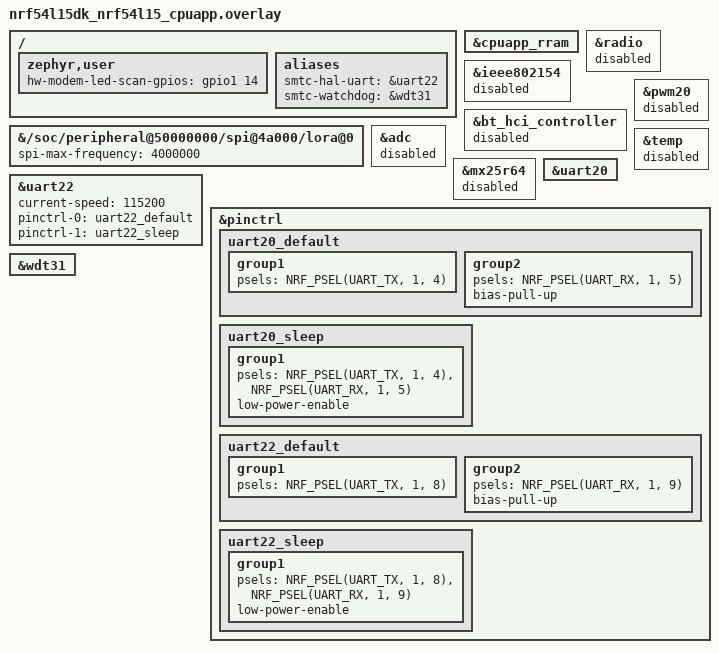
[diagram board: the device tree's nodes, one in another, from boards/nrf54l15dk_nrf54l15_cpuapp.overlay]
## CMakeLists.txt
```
# Copyright (c) 2024 Semtech Corporation
# SPDX-License-Identifier: Apache-2.0

cmake_minimum_required(VERSION 3.13.1)

find_package(Zephyr REQUIRED HINTS $ENV{ZEPHYR_BASE})
project(hw_modem)

# Use serialization files from USP module
set(USP_HW_MODEM_DIR ${ZEPHYR_USP_MODULE_DIR}/examples/main_examples/hw_modem)

zephyr_include_directories(
    ${ZEPHYR_USP_ZEPHYR_CMAKE_DIR}/include/zephyr/usp
    ${USP_HW_MODEM_DIR}
)

# Nanopb and RAC serialization
target_include_directories(app PRIVATE
  ${USP_HW_MODEM_DIR}/serialization/nanopb
  ${USP_HW_MODEM_DIR}/serialization/generated
  ${USP_HW_MODEM_DIR}/serialization/helpers
)

target_sources(app PRIVATE
  ${CMAKE_CURRENT_SOURCE_DIR}/src/main.c
  ${CMAKE_CURRENT_SOURCE_DIR}/src/hw_modem.c
  ${CMAKE_CURRENT_SOURCE_DIR}/src/unified_uart.c
  ${USP_HW_MODEM_DIR}/cmd_parser.c
  ${USP_HW_MODEM_DIR}/git_version.c

  # Nanopb core (copied to generated/ by build.sh)
  ${USP_HW_MODEM_DIR}/serialization/generated/pb_common.c
  ${USP_HW_MODEM_DIR}/serialization/generated/pb_decode.c
  ${USP_HW_MODEM_DIR}/serialization/generated/pb_encode.c

  # Generated protobuf
  ${USP_HW_MODEM_DIR}/serialization/generated/smtc_rac_context.pb.c

  # Helpers
  ${USP_HW_MODEM_DIR}/serialization/helpers/rac_context_converter.c
)

if(CONFIG_LORA_BASICS_MODEM_GEOLOCATION)
    target_sources(app PRIVATE
        ${CMAKE_CURRENT_SOURCE_DIR}/../../lbm/geolocation/src/geolocation_bsp.c
    )
endif()

# Apply the same compile definitions as LBM library
# Link against the INTERFACE library that contains all LBM compile definitions
target_link_libraries(app PRIVATE lbm_compile_definitions)

# Apply the same compile definitions as FLRP library
# Link against the INTERFACE library that contains all FLRP compile definitions
if(CONFIG_USP_FLRP)
    target_link_libraries(app PRIVATE flrp_compile_definitions)
endif()
```

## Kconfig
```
# Copyright (c) 2024 Semtech Corporation
# SPDX-License-Identifier: Apache-2.0

config USE_FLRP
	bool "Hardware modem FLRC burst commands (0xB0-0xB2)"
	default n
	depends on SEMTECH_LR20XX
	help
	  When enabled, adds FLRC burst commands and a ~20 KB static buffer in
	  cmd_parser. Use the FLRC protocol (FLRP). Requires a LR20XX radio.
	  Disable on RAM-constrained targets.

# src/unified_uart.c multiplexes modem data and log traces on a single UART using a binary
# framed protocol, and registers a custom log backend (log_backend_unified_uart) that routes
# log output through unified_uart_tx(). Zephyr's stock UART log backend and console write
# raw, unframed bytes straight to the same UART and would corrupt that framing, and printk()
# must stay routed through the log subsystem (not the UART driver) to reach the custom
# backend too. The backend's own char-out batching (src/unified_uart.c) also assumes
# immediate (synchronous, per-call) log processing. These are hard requirements of this
# sample, not tunable build options, so they are forced here instead of being left as
# settings in prj.conf.

config LOG_BACKEND_UART
	default n

config UART_CONSOLE
	default n

config LOG_OUTPUT
	default y

config LOG_PRINTK
	default y

# LOG_MODE_IMMEDIATE is a member of Zephyr's anonymous LOG_MODE choice (subsys/logging/
# Kconfig.mode): Kconfig does not let "default" or "select" force a choice member from
# another file (both are no-ops on choice symbols), so it stays set directly in prj.conf
# as CONFIG_LOG_MODE_IMMEDIATE=y — the mechanism Kconfig actually supports for picking a
# choice option from application configuration.

source "Kconfig.zephyr"
```

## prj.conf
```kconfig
# Copyright (c) 2024 Semtech Corporation
# SPDX-License-Identifier: Apache-2.0

CONFIG_DEBUG=y
CONFIG_NO_OPTIMIZATIONS=y
CONFIG_DEBUG_OPTIMIZATIONS=y
CONFIG_DEBUG_THREAD_INFO=y
CONFIG_DCACHE=n

CONFIG_USE_SEGGER_RTT=n

# ------------------------------ General configuration -------------------------

# stack size (Zephyr boilerplate + 2048 required by Semtech)
CONFIG_MAIN_STACK_SIZE=6144
CONFIG_STACK_SENTINEL=y

# some opereations will be triggered from the system workq, so match above stack size
CONFIG_SYSTEM_WORKQUEUE_STACK_SIZE=4096

# heap size
CONFIG_HEAP_MEM_POOL_SIZE=0

CONFIG_LOG=y
# CONFIG_LOG_BACKEND_UART, CONFIG_LOG_OUTPUT, CONFIG_LOG_PRINTK and CONFIG_UART_CONSOLE are
# forced in Kconfig (not user-tunable here): see the comment above the unified_uart section
# in ./Kconfig.
# CONFIG_LOG_MODE_IMMEDIATE is a choice member and Kconfig can't force those from another
# file, so it stays set here — see the comment in ./Kconfig for why it is still required.
CONFIG_LOG_MODE_IMMEDIATE=y

CONFIG_LOG_BACKEND_SHOW_COLOR=n

CONFIG_TEST_RANDOM_GENERATOR=y

CONFIG_SERIAL=y
CONFIG_UART_INTERRUPT_DRIVEN=y

CONFIG_FLASH=y

# ------------------------------ Transceiver driver ----------------------------

CONFIG_LORA_BASICS_MODEM_DRIVERS=y
# We chose to disable intermediate thread between IRQ and USP RAC Thread to make timestamping is as fast as possible
CONFIG_LORA_BASICS_MODEM_DRIVERS_EVENT_TRIGGER_NO_THREAD=y
#CONFIG_LORA_BASICS_MODEM_DRIVERS_EVENT_TRIGGER_GLOBAL_THREAD=n
#CONFIG_LORA_BASICS_MODEM_DRIVERS_EVENT_TRIGGER_OWN_THREAD=n

CONFIG_REBOOT=y

# ------------------------------ LoRa Basics Modem -----------------------------

#CONFIG_LORA_BASICS_MODEM=n
CONFIG_USP_LORA_BASICS_MODEM=y


CONFIG_LORA_BASICS_MODEM_RP2_103=y
CONFIG_LORA_BASICS_MODEM_ENABLE_ALL_REGIONS=y

# LBM LoRaWAN uses software crypto (default). FLRP adds separate *_fast sources via
# modules/flrc_protocol/common.cmake.

CONFIG_LORA_BASICS_MODEM_CLASS_B=y
CONFIG_LORA_BASICS_MODEM_CLASS_C=y
CONFIG_LORA_BASICS_MODEM_MULTICAST=y
CONFIG_LORA_BASICS_MODEM_CSMA=y

CONFIG_LORA_BASICS_MODEM_ALC_SYNC=y
CONFIG_LORA_BASICS_MODEM_ALC_SYNC_V2=y

CONFIG_LORA_BASICS_MODEM_FUOTA=y
CONFIG_LORA_BASICS_MODEM_FUOTA_V2=y
CONFIG_LORA_BASICS_MODEM_FUOTA_FMP=y
CONFIG_LORA_BASICS_MODEM_FUOTA_MPA=y

CONFIG_LORA_BASICS_MODEM_ALMANAC=y
CONFIG_LORA_BASICS_MODEM_STREAM=y
CONFIG_LORA_BASICS_MODEM_LFU=y
CONFIG_LORA_BASICS_MODEM_DEVICE_MANAGEMENT=y
CONFIG_LORA_BASICS_MODEM_GEOLOCATION=n
CONFIG_LORA_BASICS_MODEM_STORE_AND_FORWARD=y
# CONFIG_LORA_BASICS_MODEM_BEACON_TX=y
CONFIG_LORA_BASICS_MODEM_RELAY_RX=y
CONFIG_LORA_BASICS_MODEM_RELAY_TX=y

# ------------------------------ USP -----------------------------
CONFIG_USP=y
CONFIG_USP_FLRP=n # NOTE: enabling this feature will add a static 20Kb buffer
CONFIG_USP_MAIN_THREAD=n

# The following parameter disable nRF54L15 FLASH RRAM buffer size to prevent from issue being investigating
CONFIG_NRF_RRAM_WRITE_BUFFER_SIZE=0

# ------------------------------ Debug -----------------------------
```

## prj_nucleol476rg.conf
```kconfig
# Copyright (c) 2024 Semtech Corporation
# SPDX-License-Identifier: Apache-2.0

CONFIG_DEBUG=y
CONFIG_NO_OPTIMIZATIONS=y
CONFIG_DEBUG_OPTIMIZATIONS=y
CONFIG_DEBUG_THREAD_INFO=y
CONFIG_DCACHE=n

CONFIG_USE_SEGGER_RTT=n

# ------------------------------ General configuration -------------------------

# stack size (Zephyr boilerplate + 2048 required by Semtech)
CONFIG_MAIN_STACK_SIZE=12288
CONFIG_STACK_SENTINEL=y




# some opereations will be triggered from the system workq, so match above stack size
CONFIG_SYSTEM_WORKQUEUE_STACK_SIZE=8192

# heap size
CONFIG_HEAP_MEM_POOL_SIZE=8192

CONFIG_LOG=y
CONFIG_LOG_BACKEND_UART=y
CONFIG_LOG_BUFFER_SIZE=4096

CONFIG_LOG_BACKEND_SHOW_COLOR=n

CONFIG_TEST_RANDOM_GENERATOR=y

CONFIG_SERIAL=y
CONFIG_UART_INTERRUPT_DRIVEN=y

CONFIG_FLASH=y

# ------------------------------ Transceiver driver ----------------------------

CONFIG_LORA_BASICS_MODEM_DRIVERS=y
CONFIG_LORA_BASICS_MODEM_DRIVERS_EVENT_TRIGGER_GLOBAL_THREAD=y

CONFIG_REBOOT=y

# ------------------------------ LoRa Basics Modem -----------------------------

#CONFIG_LORA_BASICS_MODEM=n
CONFIG_USP_LORA_BASICS_MODEM=y


CONFIG_LORA_BASICS_MODEM_RP2_103=y
CONFIG_LORA_BASICS_MODEM_ENABLE_ALL_REGIONS=y

CONFIG_LORA_BASICS_MODEM_CRYPTOGRAPHY_SOFT=n

CONFIG_LORA_BASICS_MODEM_CLASS_B=y
CONFIG_LORA_BASICS_MODEM_CLASS_C=y
CONFIG_LORA_BASICS_MODEM_MULTICAST=y
CONFIG_LORA_BASICS_MODEM_CSMA=y

CONFIG_LORA_BASICS_MODEM_ALC_SYNC=y
CONFIG_LORA_BASICS_MODEM_ALC_SYNC_V2=y

CONFIG_LORA_BASICS_MODEM_FUOTA=y
CONFIG_LORA_BASICS_MODEM_FUOTA_V2=y
CONFIG_LORA_BASICS_MODEM_FUOTA_FMP=y
CONFIG_LORA_BASICS_MODEM_FUOTA_MPA=y

CONFIG_LORA_BASICS_MODEM_ALMANAC=y
CONFIG_LORA_BASICS_MODEM_STREAM=y
CONFIG_LORA_BASICS_MODEM_LFU=y
CONFIG_LORA_BASICS_MODEM_DEVICE_MANAGEMENT=y
CONFIG_LORA_BASICS_MODEM_GEOLOCATION=y
CONFIG_LORA_BASICS_MODEM_STORE_AND_FORWARD=y
# CONFIG_LORA_BASICS_MODEM_BEACON_TX=y
CONFIG_LORA_BASICS_MODEM_RELAY_RX=y
CONFIG_LORA_BASICS_MODEM_RELAY_TX=y

# ------------------------------ USP -----------------------------
CONFIG_USP=y
CONFIG_USP_MAIN_THREAD=n
CONFIG_PICOLIBC_USE_MODULE=n
CONFIG_NEWLIB_LIBC=y

# ------------------------------ NUCLEO L476RG CLOCK DRIFT -----------------------------
CONFIG_CORTEX_M_SYSTICK=n
CONFIG_STM32_LPTIM_TIMER=y
CONFIG_CLOCK_CONTROL=y
CONFIG_PM=y
```

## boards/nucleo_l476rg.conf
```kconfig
# Copyright (c) 2024 Semtech Corporation
# SPDX-License-Identifier: Apache-2.0

# ------------------------------ NUCLEO L476RG CLOCK DRIFT -----------------------------

# PM is required for STM32_LPTIM_TIMER but we DON'T want device PM
# Only enable system PM, not device PM to avoid UART suspension
CONFIG_PM_DEVICE=n
CONFIG_PM=y

# Prevent deep sleep to keep UART operational
# Use custom PM policy to control sleep depth
CONFIG_PM_POLICY_CUSTOM=y

# Disable SYSTICK and use LPTIM on LSE for precise clock without drift
CONFIG_CORTEX_M_SYSTICK=n
CONFIG_STM32_LPTIM_TIMER=y
CONFIG_CLOCK_CONTROL=y
CONFIG_RESET=y

# Note: LPTIM clock source (LSE 32768Hz) is configured in the device tree overlay

# Uncomment those lines to activate DMA on STM32L476RG
CONFIG_DMA=y
CONFIG_DMA_STM32=y
CONFIG_SPI_STM32_DMA=y
CONFIG_SPI_STM32_INTERRUPT=n
CONFIG_SPI_ASYNC=n
```

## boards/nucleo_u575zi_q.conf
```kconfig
# PM is required for STM32_LPTIM_TIMER but we DON'T want device PM
# Only enable system PM, not device PM to avoid UART suspension
CONFIG_PM_DEVICE=n
CONFIG_PM=y

# Prevent deep sleep to keep UART operational
# Use custom PM policy to control sleep depth
CONFIG_PM_POLICY_CUSTOM=y

# Disable SYSTICK and use LPTIM on LSE for precise clock without drift
CONFIG_CORTEX_M_SYSTICK=n
CONFIG_STM32_LPTIM_TIMER=y
CONFIG_CLOCK_CONTROL=y
```

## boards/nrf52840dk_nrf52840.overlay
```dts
/*
 * Copyright (c) 2024 Semtech Corporation
 *
 * SPDX-License-Identifier: Apache-2.0
 */

/ {
	zephyr,user {
		/* PINS used for the HW modem sample. */
		hw-modem-led-scan-gpios = <&gpio0 5 GPIO_ACTIVE_HIGH>;
	};

	aliases {
		/* Specify which UART is used for communication as input for the hw modem tester */
		smtc-hal-uart = &uart1;
		smtc-watchdog = &wdt;
	};
};

//Label for flash controller (needed cause we need properties, and we grab alias in user code)
smtc_flash: &flash0 {};

&spi1 {
	status = "disabled";
};

&qspi {
	status = "disabled"; //Needed because we use pin P0.24
};

//Delete HFC for uart0 as we use RTS pin
&uart0 {
	/delete-property/ hw-flow-control;
};

&uart1 {
	status = "okay";

	current-speed = <115200>;

	pinctrl-0 = <&uart1_default_alt>;
	pinctrl-1 = <&uart1_sleep_alt>;
	pinctrl-names = "default", "sleep";
	/delete-property/ hw-flow-control;
};

&pinctrl {
	//Disable Flow Control for uart0 (user log uart)
	uart0_default: uart0_default {
		group1 {
			psels = <NRF_PSEL(UART_TX, 0, 6)>;
		};
		group2 {
			psels = <NRF_PSEL(UART_RX, 0, 8)>;
			bias-pull-up;
		};
	};

	uart0_sleep: uart0_sleep {
		group1 {
			psels = <NRF_PSEL(UART_TX, 0, 6)>,
					<NRF_PSEL(UART_RX, 0, 8)>;
			low-power-enable;
		};
	};

	uart1_default_alt: uart1_default_alt {
		group1 {
			psels = <NRF_PSEL(UART_TX, 0, 11)>,
					<NRF_PSEL(UART_RX, 0, 12)>;
		};
	};

	uart1_sleep_alt: uart1_sleep_alt {
		group1 {
			psels = <NRF_PSEL(UART_TX, 0, 11)>,
					<NRF_PSEL(UART_RX, 0, 12)>;
			low-power-enable;
		};
	};
};

&wdt {
	status = "okay";
};

&arduino_i2c {
        /delete-property/ zephyr,concat-buf-size;
};
```

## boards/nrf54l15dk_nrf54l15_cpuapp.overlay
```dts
/*
 * Copyright (c) 2024 Semtech Corporation
 *
 * SPDX-License-Identifier: Apache-2.0
 */

/ {
	zephyr,user {
		/* PINS used for the HW modem sample. */
		hw-modem-led-scan-gpios = <&gpio1 14 GPIO_ACTIVE_HIGH>; //LED3
	};

	aliases {
		/* Specify which UART is used for communication as input for the hw modem tester */
		smtc-hal-uart = &uart22;
		smtc-watchdog = &wdt31;
	};
};

//Label for flash controller (needed cause we need properties, and we grab alias in user code)
smtc_flash: &cpuapp_rram {};

// Set SPI freq @4MHz
&{/soc/peripheral@50000000/spi@4a000/lora@0} {
	spi-max-frequency = < 4000000 >;
};

&radio {
	status = "disabled";
};

&ieee802154 {
	status = "disabled";
};

&bt_hci_controller {
	status = "disabled";
};

&pwm20 {
	status = "disabled";
};

&adc {
	status = "disabled";
};

&temp {
	status = "disabled";
};

&mx25r64 {
	status = "disabled";
};

//Bridge uart (no need flow control)
&uart22 {
	status = "okay";
	current-speed = <115200>;
	pinctrl-0 = <&uart22_default>;
	pinctrl-1 = <&uart22_sleep>;
	pinctrl-names = "default", "sleep";
	/delete-property/ hw-flow-control;
};

//User uart (for logging)
&uart20 {
	status = "okay";
	// disable-rx; //Disabling RX allows a gain of ~200µA, totally disabling uart allows another gain of ~200µA
	/delete-property/ hw-flow-control;
};

&pinctrl {
	uart20_default: uart20_default {
		group1 {
			psels = <NRF_PSEL(UART_TX, 1, 4)>
			// ,<NRF_PSEL(UART_RTS, 0, 2)>
			;
		};
		group2 {
			psels = <NRF_PSEL(UART_RX, 1, 5)>
			// ,<NRF_PSEL(UART_CTS, 0, 3)>
			;
			bias-pull-up;
		};
	};

	uart20_sleep: uart20_sleep {
		group1 {
			psels = <NRF_PSEL(UART_TX, 1, 4)>,
					<NRF_PSEL(UART_RX, 1, 5)>
					// ,<NRF_PSEL(UART_RTS, 0, 2)>
					// ,<NRF_PSEL(UART_CTS, 0, 3)>
					;
			low-power-enable;
		};
	};

	uart22_default: uart22_default {
		group1 {
			psels = <NRF_PSEL(UART_TX, 1, 8)> //BUTTON2
			// ,<NRF_PSEL(UART_RTS, 0, 2)>
			;
		};
		group2 {
			psels = <NRF_PSEL(UART_RX, 1, 9)> //BUTTON1
			// ,<NRF_PSEL(UART_CTS, 0, 3)>
			;
			bias-pull-up;
		};
	};

	uart22_sleep: uart22_sleep {
		group1 {
			psels = <NRF_PSEL(UART_TX, 1, 8)>,
					<NRF_PSEL(UART_RX, 1, 9)>
					// ,<NRF_PSEL(UART_RTS, 0, 2)>
					// ,<NRF_PSEL(UART_CTS, 0, 3)>
					;
			low-power-enable;
		};
	};
};

&wdt31 {
	status = "okay";
};
```

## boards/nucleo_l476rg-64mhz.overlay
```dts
/*
 * Copyright (c) 2024 Semtech Corporation
 *
 * SPDX-License-Identifier: Apache-2.0
 */

/ {
	zephyr,user {
		/* PINS used for the HW modem sample. */
		hw-modem-led-scan-gpios = <&gpiob 5 GPIO_ACTIVE_HIGH>;
	};

	aliases {
		/* Host UART auto-selected from chosen zephyr,console (usart2 = ST-Link VCP). */
		smtc-watchdog = &iwdg;
	};
};

//Label for flash controller (needed cause we need properties, and we grab alias in user code)
smtc_flash: &flash0 {};

// Uncomment the following 3 sections to set board @64MHz (instead of 80) and SPI@16MHz (instead of 10)
&pll {
	mul-n = <16>; 
};

&rcc {
	clock-frequency = < 64000000 >;
};

&{/soc/spi@40013000/lora@0} {
	spi-max-frequency = < 16000000 >; 
};
// END 64MHz --------------------------------------------------------

&lptim1 {
	// 0x80000000 = 31th bit of register RCC_APB1ENR1 (LPTIM1_EN)
	// We could also use ST macro : STM32_CLOCK(APB1, 31) to produce same result.
	// LPTIM1_SEL(3) = Set the LPTIM1SEL bits of RCC_CCIPR to 0b11 (source = LSE)
	clocks = <&rcc STM32_CLOCK_BUS_APB1 0x80000000>, 
		 <&rcc STM32_SRC_LSE LPTIM1_SEL(3)>;
	status = "okay";
};

&spi3 {
	status = "disabled";
};

&iwdg {
	status = "disabled";
};

&arduino_spi {
	/delete-property/ overrun-character;
};

&arduino_i2c {
        /delete-property/ zephyr,concat-buf-size;
};
```

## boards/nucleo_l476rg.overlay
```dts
/*
 * Copyright (c) 2024 Semtech Corporation
 *
 * SPDX-License-Identifier: Apache-2.0
 */

/ {
	/*
	 * Host UART is auto-selected by the sample from chosen "zephyr,console"
	 * (usart2 = ST-Link VCP on this board, set by the base board DTS).
	 * No "smtc-hal-uart" alias needed here; define one only to force a
	 * different UART than the console.
	 */
	zephyr,user {
		/* PINS used for the HW modem sample. */
		hw-modem-led-scan-gpios = <&gpiob 5 GPIO_ACTIVE_HIGH>;
	};

	aliases {
		smtc-watchdog = &iwdg;
	};
};

//Label for flash controller (needed cause we need properties, and we grab alias in user code)
smtc_flash: &flash0 {};

&lptim1 {
	clocks = <&rcc STM32_CLOCK_BUS_APB1 0x80000000>,
		 <&rcc STM32_SRC_LSE LPTIM1_SEL(3)>;
	status = "okay";
};

&spi3 {
	status = "disabled";
};

&iwdg {
	status = "disabled";
};

&arduino_spi {
	/delete-property/ overrun-character;
};

&arduino_i2c {
        /delete-property/ zephyr,concat-buf-size;
};

// Set SPI freq @10MHz for this sample
&{/soc/spi@40013000/lora@0} {
	spi-max-frequency = < 10000000 >; 
};

&arduino_spi {
        /delete-property/ overrun-character;
        // Uncomment those 3 lines to activate DMA on STM32L4
        dmas = <&dma1 3 1 (STM32_DMA_PERIPH_TX | STM32_DMA_PRIORITY_HIGH)>,
               <&dma1 2 1 (STM32_DMA_PERIPH_RX | STM32_DMA_PRIORITY_HIGH)>;
        dma-names = "tx", "rx";
};

// Uncomment those 3 lines to activate DMA on STM32L4
&dma1 {
        status = "okay";
};
```

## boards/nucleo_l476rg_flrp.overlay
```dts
/*
 * Copyright (c) 2024 Semtech Corporation
 *
 * SPDX-License-Identifier: Apache-2.0
 */

/ {
	zephyr,user {
		/* PINS used for the HW modem sample. */
		hw-modem-led-scan-gpios = <&gpiob 5 GPIO_ACTIVE_HIGH>;
	};

	aliases {
		/* Host UART auto-selected from chosen zephyr,console (usart2 = ST-Link VCP). */
		smtc-watchdog = &iwdg;
	};
};

//Label for flash controller (needed cause we need properties, and we grab alias in user code)
smtc_flash: &flash0 {};

&lptim1 {
	clocks = <&rcc STM32_CLOCK_BUS_APB1 0x80000000>,
		 <&rcc STM32_SRC_LSE LPTIM1_SEL(3)>;
	status = "okay";
};

&spi3 {
	status = "disabled";
};

&iwdg {
	status = "disabled";
};

&arduino_spi {
	/delete-property/ overrun-character;
};

&arduino_i2c {
        /delete-property/ zephyr,concat-buf-size;
};

// Set SPI freq @10MHz for this sample
&{/soc/spi@40013000/lora@0} {
	spi-max-frequency = < 10000000 >; 
        pa-ramp-time = <17>; // 272us
};

&arduino_spi {
        /delete-property/ overrun-character;
        // Uncomment those 3 lines to activate DMA on STM32L4
        dmas = <&dma1 3 1 (STM32_DMA_PERIPH_TX | STM32_DMA_PRIORITY_HIGH)>,
               <&dma1 2 1 (STM32_DMA_PERIPH_RX | STM32_DMA_PRIORITY_HIGH)>;
        dma-names = "tx", "rx";
};

// Uncomment those 3 lines to activate DMA on STM32L4
&dma1 {
        status = "okay";
};
```

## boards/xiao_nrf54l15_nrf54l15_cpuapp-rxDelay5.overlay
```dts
/*
 * Copyright (c) 2024 Semtech Corporation
 *
 * SPDX-License-Identifier: Apache-2.0
 */

/ {
	zephyr,user {
		/* PINS used for the HW modem sample. */
	};

	aliases {
		/* Host UART auto-selected from chosen zephyr,console (uart20 = USB serial). */
		smtc-watchdog = &wdt31;
	};
};

// Set rx-delay to 5*64MHz clock cycles
&xiao_spi {
	rx-delay = <5>;
};

// Host link on the USB serial (uart20 = console), already enabled @115200 by the
// base board DTS. Just turn off the unused header UART.
&uart21 {
	status = "disabled";
};

&adc {
	status = "disabled";
};

&i2c22 {
	status = "disabled";
};

&i2c30 {
	status = "disabled";
};

&wdt31 {
	status = "okay";
};

// Override xiao_nrf54l15 default configuration for USP applications
// Disable boot-on for RF switch regulators to save power

&rfsw_ctl {
	/delete-property/ regulator-boot-on;
};

&rfsw_pwr {
	/delete-property/ regulator-boot-on;
};

&vbat_pwr {
	/delete-property/ regulator-boot-on;
};
```

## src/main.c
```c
/**
 * @file      main.c
 *
 * @brief     Application main
 *
 * The Clear BSD License
 * Copyright Semtech Corporation 2025. All rights reserved.
 *
 * Redistribution and use in source and binary forms, with or without
 * modification, are permitted (subject to the limitations in the disclaimer
 * below) provided that the following conditions are met:
 *     * Redistributions of source code must retain the above copyright
 *       notice, this list of conditions and the following disclaimer.
 *     * Redistributions in binary form must reproduce the above copyright
 *       notice, this list of conditions and the following disclaimer in the
 *       documentation and/or other materials provided with the distribution.
 *     * Neither the name of the Semtech corporation nor the
 *       names of its contributors may be used to endorse or promote products
 *       derived from this software without specific prior written permission.
 *
 * NO EXPRESS OR IMPLIED LICENSES TO ANY PARTY'S PATENT RIGHTS ARE GRANTED BY
 * THIS LICENSE. THIS SOFTWARE IS PROVIDED BY THE COPYRIGHT HOLDERS AND
 * CONTRIBUTORS "AS IS" AND ANY EXPRESS OR IMPLIED WARRANTIES, INCLUDING, BUT
 * NOT LIMITED TO, THE IMPLIED WARRANTIES OF MERCHANTABILITY AND FITNESS FOR A
 * PARTICULAR PURPOSE ARE DISCLAIMED. IN NO EVENT SHALL SEMTECH CORPORATION BE
 * LIABLE FOR ANY DIRECT, INDIRECT, INCIDENTAL, SPECIAL, EXEMPLARY, OR
 * CONSEQUENTIAL DAMAGES (INCLUDING, BUT NOT LIMITED TO, PROCUREMENT OF
 * SUBSTITUTE GOODS OR SERVICES; LOSS OF USE, DATA, OR PROFITS; OR BUSINESS
 * INTERRUPTION) HOWEVER CAUSED AND ON ANY THEORY OF LIABILITY, WHETHER IN
 * CONTRACT, STRICT LIABILITY, OR TORT (INCLUDING NEGLIGENCE OR OTHERWISE)
 * ARISING IN ANY WAY OUT OF THE USE OF THIS SOFTWARE, EVEN IF ADVISED OF THE
 * POSSIBILITY OF SUCH DAMAGE.
 */

#include <stdbool.h>
#include <stdint.h>
#include <zephyr/kernel.h>
#include <zephyr/irq.h>
#include <zephyr/logging/log.h>

#include <zephyr/lorawan_lbm/lorawan_hal_init.h>
#include <smtc_modem_utilities.h>
#include <smtc_core_hal.h>
#include <smtc_rac_api.h>
#if defined( CONFIG_USP_FLRP )
#include <smtc_flrp_api.h>
#endif

#include "hw_modem.h"
#include "cmd_parser.h"
#include "git_version.h"

LOG_MODULE_REGISTER( hw_modem, LOG_LEVEL_INF );

/**
 * @brief Watchdog counter reload value during sleep (The period must be lower than MCU watchdog
 * period (here 32s))
 */
#define WATCHDOG_RELOAD_PERIOD_MS 20000

/* lr11xx radio context and its use in the ralf layer */
static const struct device* transceiver = DEVICE_DT_GET( DT_ALIAS( lora_transceiver ) );

/**
 * @brief Callback for modem hal
 */
static uint8_t prv_get_battery_level_cb( void )
{
    return 98;
}

/**
 * @brief Callback for modem hal
 */
static uint16_t prv_get_battery_voltage_cb( void )
{
    return 3300;
}

/**
 * @brief Callback for modem hal
 */
static int8_t prv_get_temperature_cb( void )
{
    return 25;
}

#ifdef CONFIG_LORA_BASICS_MODEM_FUOTA
static uint32_t prv_get_hw_version_for_fuota( void )
{
    return 1;
}

static uint32_t prv_get_fw_version_for_fuota( void )
{
    return 1;
}

static uint8_t prv_get_fw_status_available_for_fuota( void )
{
    return 1;
}

static uint32_t prv_get_next_fw_version_for_fuota( void )
{
    return 1;
}

static uint8_t prv_get_fw_delete_status_for_fuota( uint32_t version )
{
    return 0;
}

/* Callbacks for HAL implementation */
static struct lorawan_fuota_cb prv_fuota_cb = {
    .get_hw_version          = prv_get_hw_version_for_fuota,
    .get_fw_version          = prv_get_fw_version_for_fuota,
    .get_fw_status_available = prv_get_fw_status_available_for_fuota,
    .get_next_fw_version     = prv_get_next_fw_version_for_fuota,
    .get_fw_delete_status    = prv_get_fw_delete_status_for_fuota,
};

#endif /* CONFIG_LORA_BASICS_MODEM_FUOTA */

void main_hw_modem( void );

int main( void )
{
    unsigned int irq_lock_key;
    uint32_t     sleep_time_ms = 0;
    bool         is_sleep_ok;

    lorawan_smtc_modem_hal_init( transceiver );
    lorawan_register_battery_level_callback( prv_get_battery_level_cb );
    lorawan_register_battery_voltage_callback( prv_get_battery_voltage_cb );
    lorawan_register_temperature_callback( prv_get_temperature_cb );
#ifdef CONFIG_LORA_BASICS_MODEM_FUOTA
    lorawan_register_fuota_callbacks( &prv_fuota_cb );
#endif

    cmd_parser_set_transceiver_context( ( void* ) transceiver );

    /* NOTE: watchdogs aren't fully implemented in those samples. */
    /* hal_watchdog_init(); */

    // Initialize RAC
    smtc_rac_init( );

    if( hw_modem_init( ) )
    {
        LOG_ERR( "Could not initialize hardware modem, exiting." );
        return 0;
    }

    LOG_INF( "Modem is starting" );
    LOG_DBG( "Commit SHA1: %s", get_software_git_commit( ) );
    LOG_DBG( "Commit date: %s", get_software_git_date( ) );
    LOG_DBG( "Build date: %s", get_software_build_date( ) );

    while( 1 )
    {
        /* Check if a command is available */
        if( hw_modem_is_a_cmd_available( ) == true )
        {
            /* Command may generate work for the stack, so drop down to
             * smtc_modem_run_engine().
             */
            hw_modem_process_cmd( );
        }

        /* Modem process launch */
        sleep_time_ms = smtc_modem_run_engine( );
        smtc_rac_run_engine( );
#if defined( CONFIG_USP_FLRP )
        smtc_flrp_run_engine( );
        if( smtc_rac_is_irq_flag_pending( ) )
        {
            continue;
        }
#endif

        /* Check sleep conditions (no command available and low power is possible) */
        irq_lock_key = irq_lock( );
        is_sleep_ok  = ( hw_modem_is_a_cmd_available( ) == false ) && ( hw_modem_is_low_power_ok( ) == true ) &&
                      ( smtc_modem_is_irq_flag_pending( ) == false );
        irq_unlock( irq_lock_key );

        if( is_sleep_ok )
        {
            uint32_t real_sleep_time_ms = MIN( sleep_time_ms, WATCHDOG_RELOAD_PERIOD_MS );

            LOG_DBG( "Sleeping for %d ms", real_sleep_time_ms );
            smtc_modem_hal_interruptible_msleep( real_sleep_time_ms );
        }
    }
    return 0;
}
```

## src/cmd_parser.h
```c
/**
 * @file      cmd_parser.h
 *
 * @brief     cmd_parser implementation
 *
 * The Clear BSD License
 * Copyright Semtech Corporation 2025. All rights reserved.
 *
 * Redistribution and use in source and binary forms, with or without
 * modification, are permitted (subject to the limitations in the disclaimer
 * below) provided that the following conditions are met:
 *     * Redistributions of source code must retain the above copyright
 *       notice, this list of conditions and the following disclaimer.
 *     * Redistributions in binary form must reproduce the above copyright
 *       notice, this list of conditions and the following disclaimer in the
 *       documentation and/or other materials provided with the distribution.
 *     * Neither the name of the Semtech corporation nor the
 *       names of its contributors may be used to endorse or promote products
 *       derived from this software without specific prior written permission.
 *
 * NO EXPRESS OR IMPLIED LICENSES TO ANY PARTY'S PATENT RIGHTS ARE GRANTED BY
 * THIS LICENSE. THIS SOFTWARE IS PROVIDED BY THE COPYRIGHT HOLDERS AND
 * CONTRIBUTORS "AS IS" AND ANY EXPRESS OR IMPLIED WARRANTIES, INCLUDING, BUT
 * NOT LIMITED TO, THE IMPLIED WARRANTIES OF MERCHANTABILITY AND FITNESS FOR A
 * PARTICULAR PURPOSE ARE DISCLAIMED. IN NO EVENT SHALL SEMTECH CORPORATION BE
 * LIABLE FOR ANY DIRECT, INDIRECT, INCIDENTAL, SPECIAL, EXEMPLARY, OR
 * CONSEQUENTIAL DAMAGES (INCLUDING, BUT NOT LIMITED TO, PROCUREMENT OF
 * SUBSTITUTE GOODS OR SERVICES; LOSS OF USE, DATA, OR PROFITS; OR BUSINESS
 * INTERRUPTION) HOWEVER CAUSED AND ON ANY THEORY OF LIABILITY, WHETHER IN
 * CONTRACT, STRICT LIABILITY, OR TORT (INCLUDING NEGLIGENCE OR OTHERWISE)
 * ARISING IN ANY WAY OUT OF THE USE OF THIS SOFTWARE, EVEN IF ADVISED OF THE
 * POSSIBILITY OF SUCH DAMAGE.
 */

#ifndef CMD_PARSER_H__
#define CMD_PARSER_H__

#include <stdint.h>

#include "smtc_modem_api.h"

#ifdef __cplusplus
extern "C" {
#endif

/**
 * @brief Host command opcode definition
 */
typedef enum host_cmd_id_e
{
    CMD_RESET                                = 0x00,
    CMD_SET_REGION                           = 0x01,
    CMD_GET_REGION                           = 0x02,
    CMD_JOIN_NETWORK                         = 0x03,
    CMD_REQUEST_UPLINK                       = 0x04,
    CMD_GET_EVENT                            = 0x05,
    CMD_GET_DOWNLINK_DATA                    = 0x06,
    CMD_GET_DOWNLINK_METADATA                = 0x07,
    CMD_GET_JOIN_EUI                         = 0x08,
    CMD_SET_JOIN_EUI                         = 0x09,
    CMD_GET_DEV_EUI                          = 0x0A,
    CMD_SET_DEV_EUI                          = 0x0B,
    CMD_SET_NWKKEY                           = 0x0C,
    CMD_GET_PIN                              = 0x0D,
    CMD_GET_CHIP_EUI                         = 0x0E,
    CMD_DERIVE_KEYS                          = 0x0F,
    CMD_GET_MODEM_VERSION                    = 0x10,
    CMD_LORAWAN_GET_LOST_CONNECTION_COUNTER  = 0x11,
    CMD_SET_CERTIFICATION_MODE               = 0x12,
    CMD_EMERGENCY_UPLINK                     = 0x13,
    CMD_REQUEST_EMPTY_UPLINK                 = 0x14,
    CMD_LEAVE_NETWORK                        = 0x15,
    CMD_ALARM_START_TIMER                    = 0x16,
    CMD_ALARM_CLEAR_TIMER                    = 0x17,
    CMD_ALARM_GET_REMAINING_TIME             = 0x18,
    CMD_GET_NEXT_TX_MAX_PAYLOAD              = 0x19,
    CMD_GET_DUTY_CYCLE_STATUS                = 0x1A,
    CMD_SET_NETWORK_TYPE                     = 0x1B,
    CMD_SET_JOIN_DR_DISTRIBUTION             = 0x1C,
    CMD_SET_ADR_PROFILE                      = 0x1D,
    CMD_SET_NB_TRANS                         = 0x1E,
    CMD_GET_NB_TRANS                         = 0x1F,
    CMD_GET_ENABLED_DATARATE                 = 0x20,
    CMD_SET_ADR_ACK_LIMIT_DELAY              = 0x21,
    CMD_GET_ADR_ACK_LIMIT_DELAY              = 0x22,
    CMD_SET_CRYSTAL_ERR                      = 0x23,
    CMD_LBT_SET_PARAMS                       = 0x24,
    CMD_LBT_GET_PARAMS                       = 0x25,
    CMD_LBT_SET_STATE                        = 0x26,
    CMD_LBT_GET_STATE                        = 0x27,
    CMD_GET_CHARGE                           = 0x28,
    CMD_RESET_CHARGE                         = 0x29,
    CMD_SET_CLASS                            = 0x2A,
    CMD_CLASS_B_SET_PING_SLOT_PERIODICITY    = 0x2B,
    CMD_CLASS_B_GET_PING_SLOT_PERIODICITY    = 0x2C,
    CMD_MULTICAST_SET_GROUP_CONFIG           = 0x2D,
    CMD_MULTICAST_GET_GROUP_CONFIG           = 0x2E,
    CMD_MULTICAST_CLASS_C_START_SESSION      = 0x2F,
    CMD_MULTICAST_CLASS_C_GET_SESSION_STATUS = 0x30,
    CMD_MULTICAST_CLASS_C_STOP_SESSION       = 0x31,
    CMD_MULTICAST_CLASS_C_STOP_ALL_SESSIONS  = 0x32,
    CMD_MULTICAST_CLASS_B_START_SESSION      = 0x33,
    CMD_MULTICAST_CLASS_B_GET_SESSION_STATUS = 0x34,
    CMD_MULTICAST_CLASS_B_STOP_SESSION       = 0x35,
    CMD_MULTICAST_CLASS_B_STOP_ALL_SESSIONS  = 0x36,
    CMD_START_ALCSYNC_SERVICE                = 0x37,
    CMD_STOP_ALCSYNC_SERVICE                 = 0x38,
    CMD_GET_ALCSYNC_TIME                     = 0x39,
    CMD_TRIG_ALCSYNC_REQUEST                 = 0x3A,
    CMD_LORAWAN_MAC_REQUEST                  = 0x3B,
    CMD_GET_LORAWAN_TIME                     = 0x3C,
    CMD_GET_LINK_CHECK_DATA                  = 0x3D,
    CMD_SET_DUTY_CYCLE_STATE                 = 0x3E,
    CMD_DEBUG_CONNECT_WITH_ABP               = 0x3F,
    CMD_TEST                                 = 0x40,
    CMD_SET_TX_POWER_OFFSET                  = 0x41,
    CMD_GET_TX_POWER_OFFSET                  = 0x42,
    CMD_CSMA_SET_STATE                       = 0x43,
    CMD_CSMA_GET_STATE                       = 0x44,
    CMD_CSMA_SET_PARAMETERS                  = 0x45,
    CMD_CSMA_GET_PARAMETERS                  = 0x46,
    CMD_STREAM_INIT                          = 0x47,
    CMD_STREAM_ADD_DATA                      = 0x48,
    CMD_STREAM_STATUS                        = 0x49,
    CMD_LFU_INIT                             = 0x4A,
    CMD_LFU_DATA                             = 0x4B,
    CMD_LFU_START                            = 0x4C,
    CMD_LFU_RESET                            = 0x4D,
    CMD_DM_ENABLE                            = 0x4E,
    CMD_DM_GET_PORT                          = 0x4F,
    CMD_DM_SET_PORT                          = 0x50,
    CMD_DM_GET_INFO_INTERVAL                 = 0x51,
    CMD_DM_SET_INFO_INTERVAL                 = 0x52,
    CMD_DM_GET_PERIODIC_INFO_FIELDS          = 0x53,
    CMD_DM_SET_PERIODIC_INFO_FIELDS          = 0x54,
    CMD_DM_REQUEST_IMMEDIATE_INFO_FIELDS     = 0x55,
    CMD_DM_SET_USER_DATA                     = 0x56,
    CMD_DM_GET_USER_DATA                     = 0x57,
    CMD_GET_STATUS                           = 0x58,
    CMD_SUSPEND_RADIO_COMMUNICATIONS         = 0x59,
    CMD_DM_HANDLE_ALCSYNC                    = 0x5A,
    CMD_SET_APPKEY                           = 0x5B,
    CMD_GET_ADR_PROFILE                      = 0x5C,
    CMD_GET_CERTIFICATION_MODE               = 0x5D,
    CMD_STORE_AND_FORWARD_SET_STATE          = 0x5E,
    CMD_STORE_AND_FORWARD_GET_STATE          = 0x5F,
    CMD_STORE_AND_FORWARD_ADD_DATA           = 0x60,
    CMD_STORE_AND_FORWARD_CLEAR_DATA         = 0x61,
    CMD_STORE_AND_FORWARD_GET_FREE_SLOT      = 0x62,
#if defined( CONFIG_LORA_BASICS_MODEM_GEOLOCATION )
    CMD_GNSS_SCAN                             = 0x70,
    CMD_GNSS_SCAN_CANCEL                      = 0x71,
    CMD_GNSS_GET_EVENT_DATA_SCAN_DONE         = 0x72,
    CMD_GNSS_GET_SCAN_DONE_RAW_DATA_LIST      = 0x73,
    CMD_GNSS_GET_SCAN_DONE_METADATA_LIST      = 0x74,
    CMD_GNSS_GET_SCAN_DONE_SCAN_SV            = 0x75,
    CMD_GNSS_GET_EVENT_DATA_TERMINATED        = 0x76,
    CMD_GNSS_SET_CONST                        = 0x77,
    CMD_GNSS_SET_PORT                         = 0x78,
    CMD_GNSS_SCAN_AGGREGATE                   = 0x79,
    CMD_GNSS_SEND_MODE                        = 0x7A,
    CMD_GNSS_ALM_DEMOD_START                  = 0x7B,
    CMD_GNSS_ALM_DEMOD_SET_CONSTEL            = 0x7C,
    CMD_GNSS_ALM_DEMOD_GET_EVENT_DATA_ALM_UPD = 0x7D,
    CMD_CLOUD_ALMANAC_START                   = 0x7E,
    CMD_CLOUD_ALMANAC_STOP                    = 0x7F,
    CMD_WIFI_SCAN_START                       = 0x80,
    CMD_WIFI_SCAN_CANCEL                      = 0x81,
    CMD_WIFI_GET_SCAN_DONE_SCAN_DATA          = 0x82,
    CMD_WIFI_GET_EVENT_DATA_TERMINATED        = 0x83,
    CMD_WIFI_SET_PORT                         = 0x84,
    CMD_WIFI_SEND_MODE                        = 0x85,
    CMD_WIFI_SET_PAYLOAD_FORMAT               = 0x86,
    CMD_LR11XX_RADIO_READ                     = 0x90,
    CMD_LR11XX_RADIO_WRITE                    = 0x91,
#endif /* CONFIG_LORA_BASICS_MODEM_GEOLOCATION */
    CMD_SET_RTC_OFFSET = 0x92,
#if defined( CONFIG_LORA_BASICS_MODEM_RELAY_TX )
    CMD_SET_RELAY_CONFIG = 0x93,
    CMD_GET_RELAY_CONFIG = 0x94,
#endif /* CONFIG_LORA_BASICS_MODEM_RELAY_TX */
    CMD_GET_SUSPEND_RADIO_COMMUNICATIONS       = 0x95,
    CMD_GET_BYPASS_JOIN_DUTY_CYCLE_BACKOFF     = 0x96,
    CMD_SET_BYPASS_JOIN_DUTY_CYCLE_BACKOFF     = 0x97,
    CMD_MODEM_GET_CRASHLOG                     = 0x98,
    CMD_MODEM_GET_REPORT_ALL_DOWNLINKS_TO_USER = 0x99,
    CMD_MODEM_SET_REPORT_ALL_DOWNLINKS_TO_USER = 0x9A,

    CMD_USP_SUBMIT = 0xA0,
    CMD_USP_OPEN   = 0xA2,
    CMD_USP_CLOSE  = 0xA3,
    CMD_USP_ABORT  = 0xA4,
    /* CMD_USP_GET_RESULTS removed - use NHM_CMD_USP_GET_RESULTS via CMD_NHM_EXTENDED instead */

    /* NHM (New Hw Modem) Protocol - Extended commands */
    CMD_NHM_EXTENDED = 0xA6,

    CMD_MAX
} host_cmd_id_t;

/**
 * @brief Host test command opcode definition
 */
typedef enum host_cmd_test_id_e
{
    CMD_TST_START            = 0x00,
    CMD_TST_EXIT             = 0x01,
    CMD_TST_NOP              = 0x02,
    CMD_TST_TX_LORA          = 0x03,
    CMD_TST_TX_FSK           = 0x04,
    CMD_TST_TX_LRFHSS        = 0x05,
    CMD_TST_TX_CW            = 0x06,
    CMD_TST_RX_LORA          = 0x07,
    CMD_TST_RX_FSK_CONT      = 0x08,
    CMD_TST_READ_NB_PKTS_RX  = 0x09,
    CMD_TST_READ_LAST_RX_PKT = 0x0A,
    CMD_TST_RSSI             = 0x0B,
    CMD_TST_RSSI_GET         = 0x0C,
    CMD_TST_RADIO_RST        = 0x0D,
    CMD_TST_BUSYLOOP         = 0x0E,
    CMD_TST_PANIC            = 0x0F,
    CMD_TST_WATCHDOG         = 0x10,
    CMD_TST_RADIO_READ       = 0x11,
    CMD_TST_RADIO_WRITE      = 0x12,
    CMD_TST_MAX
} host_cmd_test_id_t;

/**
 * @brief Command parser serial return code
 */
typedef enum cmd_serial_rc_code_e
{
    CMD_RC_OK               = 0x00,
    CMD_RC_UNKNOWN          = 0x01,
    CMD_RC_NOT_IMPLEMENTED  = 0x02,
    CMD_RC_NOT_INIT         = 0x03,
    CMD_RC_INVALID          = 0x04,
    CMD_RC_BUSY             = 0x05,
    CMD_RC_FAIL             = 0x06,
    CMD_RC_BAD_CRC          = 0x08,
    CMD_RC_BAD_SIZE         = 0x0A,
    CMD_RC_FRAME_ERROR      = 0x0F,
    CMD_RC_NO_TIME          = 0x10,
    CMD_RC_INVALID_STACK_ID = 0x11,
    CMD_RC_NO_EVENT         = 0x12,
} cmd_serial_rc_code_t;

/**
 * @brief Input command structure
 */
typedef struct cmd_input_e
{
    host_cmd_id_t cmd_code;
    uint8_t       length;
    uint8_t*      buffer;
} cmd_input_t;

/**
 * @brief Command response struture
 */
typedef struct cmd_response_e
{
    cmd_serial_rc_code_t return_code;
    uint8_t              length;
    uint8_t*             buffer;
} cmd_response_t;

/**
 * @brief Input test command structure
 */
typedef struct cmd_tst_response_e
{
    cmd_serial_rc_code_t return_code;
    uint8_t              length;
    uint8_t*             buffer;
} cmd_tst_response_t;

/**
 * @brief Test command response struture
 */
typedef struct cmd_tst_input_e
{
    host_cmd_test_id_t cmd_code;
    uint8_t            length;
    uint8_t*           buffer;
} cmd_tst_input_t;

/**
 * @brief Command parser status
 */
typedef enum cmd_parse_status_e
{
    PARSE_ERROR,
    PARSE_OK,
} cmd_parse_status_t;

/* ============================================================================ */
/* NHM (New Hw Modem) Protocol Definitions                                     */
/* ============================================================================ */

/**
 * @brief NHM message types (3 bits - UCI compatible)
 */
typedef enum nhm_message_type_e
{
    NHM_MT_RFU          = 0, /*!< Reserved for future use */
    NHM_MT_COMMAND      = 1, /*!< Command message */
    NHM_MT_RESPONSE     = 2, /*!< Response message */
    NHM_MT_NOTIFICATION = 3, /*!< Notification message */
    /* 4-7 Reserved for future use */
} nhm_message_type_t;

/**
 * @brief NHM packet boundary flag for segmentation (1 bit - UCI compatible)
 */
typedef enum nhm_packet_boundary_e
{
    NHM_PBF_COMPLETE_OR_LAST = 0, /*!< Complete message OR last segment of fragmented message */
    NHM_PBF_NOT_LAST         = 1  /*!< Intermediate segment (not the last segment) */
} nhm_packet_boundary_t;

/**
 * @brief NHM extended command IDs (12-bit addressing = 4096 commands)
 */
typedef enum nhm_cmd_id_e
{
    NHM_CMD_USP_SUBMIT           = 0x100, /*!< USP/RAC submit command (replaces CMD_USP_SUBMIT for large packets) */
    NHM_CMD_USP_GET_RESULTS      = 0x102, /*!< USP/RAC get results (replaces CMD_USP_GET_RESULTS) */
    NHM_CMD_USP_GET_NEXT_SEGMENT = 0x103, /*!< USP/RAC get next segment */
} nhm_cmd_id_t;

/**
 * @brief NHM protocol header structure (4 bytes) - UCI inspired format
 *
 * Format: [MT+PBF+ID_HIGH][ID_LOW][RFU][LENGTH]
 * - Byte 0: MT[7:5] + PBF[4] + ID_High[3:0] (UCI compatible)
 * - Byte 1: ID_Low[7:0] (total 12-bit command ID = 4096 commands)
 * - Byte 2: RFU (Reserved for Future Use)
 * - Byte 3: Payload length (0-251 bytes)
 *
 * Field details:
 * • MT (Message Type): 3 bits - Command(1)/Response(2)/Notification(3)
 * • PBF (Packet Boundary Flag): 1 bit - Complete/Last(0) vs Intermediate(1)
 * • ID_High: 4 bits - High part of 12-bit command identifier
 * • ID_Low: 8 bits - Low part of 12-bit command identifier
 * • RFU: 8 bits - Reserved for future protocol extensions
 * • Length: 8 bits - Payload size (max 251 bytes per packet)
 */
typedef struct nhm_header_e
{
    uint8_t mt_pbf_id_high; /*!< MT[7:5] + PBF[4] + ID_High[3:0] */
    uint8_t id_low;         /*!< ID_Low[7:0] - Command ID low 8 bits */
    uint8_t rfu;            /*!< Reserved for future use */
    uint8_t length;         /*!< Payload length (0-251 bytes) */
} nhm_header_t;

/**
 * @brief NHM packet structure
 */
typedef struct nhm_packet_e
{
    nhm_header_t header;  /*!< NHM header */
    uint8_t*     payload; /*!< Pointer to payload data */
} nhm_packet_t;

/**
 * @brief NHM segmentation state
 */
typedef struct nhm_segmentation_state_e
{
    uint16_t cmd_id;      /*!< Command ID being segmented (0 = no segmentation) */
    uint16_t current_pos; /*!< Current buffer position (0 = no segmentation) */
} nhm_segmentation_state_t;

typedef struct nhm_segmentation_rsp_state_e
{
    uint16_t cmd_id;       /*!< Command ID being segmented (0 = no segmentation) */
    uint16_t current_pos;  /*!< Current buffer position (0 = no segmentation) */
    uint16_t total_length; /*!< Total length of answer */
} nhm_segmentation_rsp_state_t;

/* Helper macros for NHM header manipulation (UCI compatible) */
#define NHM_HEADER_GET_MT( header ) ( ( ( header )->mt_pbf_id_high >> 5 ) & 0x07 )
#define NHM_HEADER_GET_PBF( header ) ( ( ( header )->mt_pbf_id_high >> 4 ) & 0x01 )
#define NHM_HEADER_GET_CMD_ID( header ) ( ( ( ( header )->mt_pbf_id_high & 0x0F ) << 8 ) | ( header )->id_low )

#define NHM_HEADER_SET_MT( header, mt ) \
    ( ( header )->mt_pbf_id_high = ( ( header )->mt_pbf_id_high & 0x1F ) | ( ( ( mt ) & 0x07 ) << 5 ) )
#define NHM_HEADER_SET_PBF( header, pbf ) \
    ( ( header )->mt_pbf_id_high = ( ( header )->mt_pbf_id_high & 0xEF ) | ( ( ( pbf ) & 0x01 ) << 4 ) )
#define NHM_HEADER_SET_CMD_ID_HIGH( header, cmd_id ) \
    ( ( header )->mt_pbf_id_high = ( ( header )->mt_pbf_id_high & 0xF0 ) | ( ( ( cmd_id ) >> 8 ) & 0x0F ) )
#define NHM_HEADER_SET_CMD_ID_LOW( header, cmd_id ) ( ( header )->id_low = ( cmd_id ) & 0xFF )
#define NHM_HEADER_SET_CMD_ID( header, cmd_id )       \
    do                                                \
    {                                                 \
        NHM_HEADER_SET_CMD_ID_HIGH( header, cmd_id ); \
        NHM_HEADER_SET_CMD_ID_LOW( header, cmd_id );  \
    } while( 0 )
#define NHM_HEADER_SET_MT_PBF_ID( mt, pbf, cmd_id ) \
    ( ( ( ( mt ) & 0x07 ) << 5 ) | ( ( ( pbf ) & 0x01 ) << 4 ) | ( ( ( cmd_id ) >> 8 ) & 0x0F ) )
#define NHM_HEADER_SET_ALL( header, mt, pbf, cmd_id, length )                     \
    do                                                                            \
    {                                                                             \
        ( header )->mt_pbf_id_high = NHM_HEADER_SET_MT_PBF_ID( mt, pbf, cmd_id ); \
        ( header )->id_low         = ( cmd_id ) & 0xFF;                           \
        ( header )->rfu            = 0;                                           \
        ( header )->length         = ( length );                                  \
    } while( 0 )

/* NHM Constants */
#define NHM_MAX_PAYLOAD_SIZE 251       /*!< Max payload per packet (255 - 4 header bytes) */
#define NHM_REASSEMBLY_BUFFER_SIZE 700 /*!< Max reassembled message size */
#define NHM_HEADER_SIZE 4              /*!< NHM header size in bytes */

/**
 * @brief Parse command received on serial link
 *
 * @param [in]  cmd_input  Contains the command received
 * @param [out] cmd_output Contains the response to the received command
 * @return cmd_parse_status_t
 */
cmd_parse_status_t parse_cmd( cmd_input_t* cmd_input, cmd_response_t* cmd_output );

/**
 * @brief Parse test command received on serial link
 *
 * @param [in] cmd_tst_input   Contains the command received
 * @param [out] cmd_tst_output Contains the response to the received command
 * @return cmd_parse_status_t
 */
cmd_parse_status_t cmd_test_parser( cmd_tst_input_t* cmd_tst_input, cmd_tst_response_t* cmd_tst_output );

/**
 * @brief Parse NHM (New Hw Modem) extended command
 *
 * @param [in]  cmd_input  Contains the NHM command received
 * @param [out] cmd_output Contains the response to the received NHM command
 * @return cmd_parse_status_t
 */
cmd_parse_status_t parse_nhm_cmd( cmd_input_t* cmd_input, cmd_response_t* cmd_output );

/**
 * @brief Handle NHM complete packet (no segmentation)
 *
 * @param [in]  nhm_cmd_id NHM command ID
 * @param [in]  payload    Pointer to payload data
 * @param [in]  length     Payload length
 * @param [out] cmd_output Contains the response
 * @return cmd_parse_status_t
 */
cmd_parse_status_t handle_nhm_complete_packet( uint16_t nhm_cmd_id, uint8_t* payload, uint16_t length,
                                               cmd_response_t* cmd_output );

/* Workaround for internal calls requiring a pointer to the transceiver context */

void cmd_parser_set_transceiver_context( void* context );

#ifdef __cplusplus
}
#endif

#endif /* CMD_PARSER_H__ */
```

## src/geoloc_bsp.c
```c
/**
 * @file      geoloc_bsp.c
 *
 * @brief     geoloc_bsp BSP implementation
 *
 * The Clear BSD License
 * Copyright Semtech Corporation 2025. All rights reserved.
 *
 * Redistribution and use in source and binary forms, with or without
 * modification, are permitted (subject to the limitations in the disclaimer
 * below) provided that the following conditions are met:
 *     * Redistributions of source code must retain the above copyright
 *       notice, this list of conditions and the following disclaimer.
 *     * Redistributions in binary form must reproduce the above copyright
 *       notice, this list of conditions and the following disclaimer in the
 *       documentation and/or other materials provided with the distribution.
 *     * Neither the name of the Semtech corporation nor the
 *       names of its contributors may be used to endorse or promote products
 *       derived from this software without specific prior written permission.
 *
 * NO EXPRESS OR IMPLIED LICENSES TO ANY PARTY'S PATENT RIGHTS ARE GRANTED BY
 * THIS LICENSE. THIS SOFTWARE IS PROVIDED BY THE COPYRIGHT HOLDERS AND
 * CONTRIBUTORS "AS IS" AND ANY EXPRESS OR IMPLIED WARRANTIES, INCLUDING, BUT
 * NOT LIMITED TO, THE IMPLIED WARRANTIES OF MERCHANTABILITY AND FITNESS FOR A
 * PARTICULAR PURPOSE ARE DISCLAIMED. IN NO EVENT SHALL SEMTECH CORPORATION BE
 * LIABLE FOR ANY DIRECT, INDIRECT, INCIDENTAL, SPECIAL, EXEMPLARY, OR
 * CONSEQUENTIAL DAMAGES (INCLUDING, BUT NOT LIMITED TO, PROCUREMENT OF
 * SUBSTITUTE GOODS OR SERVICES; LOSS OF USE, DATA, OR PROFITS; OR BUSINESS
 * INTERRUPTION) HOWEVER CAUSED AND ON ANY THEORY OF LIABILITY, WHETHER IN
 * CONTRACT, STRICT LIABILITY, OR TORT (INCLUDING NEGLIGENCE OR OTHERWISE)
 * ARISING IN ANY WAY OUT OF THE USE OF THIS SOFTWARE, EVEN IF ADVISED OF THE
 * POSSIBILITY OF SUCH DAMAGE.
 */

// This file is compiled only if CONFIG_LORA_BASICS_MODEM_GEOLOCATION is set.

#include <zephyr/kernel.h>
#include <zephyr/drivers/gpio.h>

#include "geolocation_bsp.h"

// It is possible that some shields embeds a geoloc-compatible radio, but no external LNA pin and/or led scan pin.
// Hence, the GPIO pin definitions won't be in the device tree source.
// In this case, the prescan_actions and postscan_actions won't do anything.
// We still have to handle these cases to prevent compilation errors.
// There is probably a Zephyry-way to pass an optional default argument such as GPIO_DT_SPEC_GET_OR, and create a dummy
// GPIO struct that won't do anything when toggled.
// P.S User can also choose to add or override shield gpio definitions.

#define LBM_DTS_HAS_LED_SCAN DT_NODE_EXISTS( DT_NODELABEL( lora_scanning_led ) )
#define LBM_DTS_HAS_LNA_CTRL DT_NODE_EXISTS( DT_NODELABEL( lora_gnss_lna_control ) )

// Get the GPIO struct for GNSS LNA directly from shield DTS
#if LBM_DTS_HAS_LED_SCAN
static const struct gpio_dt_spec hw_modem_led_scan_gpios = GPIO_DT_SPEC_GET( DT_NODELABEL( lora_scanning_led ), gpios );
#endif

#if LBM_DTS_HAS_LNA_CTRL
static const struct gpio_dt_spec hw_modem_gnss_lna_ctrl =
    GPIO_DT_SPEC_GET( DT_NODELABEL( lora_gnss_lna_control ), gpios );
#endif

void geolocation_bsp_gnss_prescan_actions( void )
{
#if LBM_DTS_HAS_LED_SCAN
    gpio_pin_set_dt( &hw_modem_led_scan_gpios, 1 );
#endif
#if LBM_DTS_HAS_LNA_CTRL
    gpio_pin_set_dt( &hw_modem_gnss_lna_ctrl, 1 );
#endif
}

void geolocation_bsp_gnss_postscan_actions( void )
{
#if LBM_DTS_HAS_LED_SCAN
    gpio_pin_set_dt( &hw_modem_led_scan_gpios, 0 );
#endif
#if LBM_DTS_HAS_LNA_CTRL
    gpio_pin_set_dt( &hw_modem_gnss_lna_ctrl, 0 );
#endif
}

void geolocation_bsp_wifi_prescan_actions( void )
{
#if LBM_DTS_HAS_LED_SCAN
    gpio_pin_set_dt( &hw_modem_led_scan_gpios, 1 );
#endif
}

void geolocation_bsp_wifi_postscan_actions( void )
{
#if LBM_DTS_HAS_LED_SCAN
    gpio_pin_set_dt( &hw_modem_led_scan_gpios, 0 );
#endif
}

lr11xx_system_lfclk_cfg_t geolocation_bsp_get_lr11xx_lf_clock_cfg( void )
{
    return LR11XX_SYSTEM_LFCLK_XTAL;
}

void geolocation_bsp_get_lr11xx_reg_mode( const void* context, lr11xx_system_reg_mode_t* reg_mode )
{
    *reg_mode = LR11XX_SYSTEM_REG_MODE_DCDC;
}

void geolocation_bsp_gnss_get_consumption(
    lr11xx_gnss_instantaneous_power_consumption_ua_t* instantaneous_power_consumption_ua )
{
    /* These value are for EVK board in DC DC mode with Xtal 32KHz and a TCXO 32MHz*/
    instantaneous_power_consumption_ua->board_voltage_mv            = 3300;
    instantaneous_power_consumption_ua->init_ua                     = 3150;
    instantaneous_power_consumption_ua->phase1_gps_capture_ua       = 11900;
    instantaneous_power_consumption_ua->phase1_gps_process_ua       = 3340;
    instantaneous_power_consumption_ua->multiscan_gps_capture_ua    = 10700;
    instantaneous_power_consumption_ua->multiscan_gps_process_ua    = 4180;
    instantaneous_power_consumption_ua->phase1_beidou_capture_ua    = 13500;
    instantaneous_power_consumption_ua->phase1_beidou_process_ua    = 3190;
    instantaneous_power_consumption_ua->multiscan_beidou_capture_ua = 12600;
    instantaneous_power_consumption_ua->multiscan_beidou_process_ua = 3430;
    instantaneous_power_consumption_ua->sleep_32k_ua                = 1210;
    instantaneous_power_consumption_ua->demod_sleep_32m_ua          = 2530;
}
```
